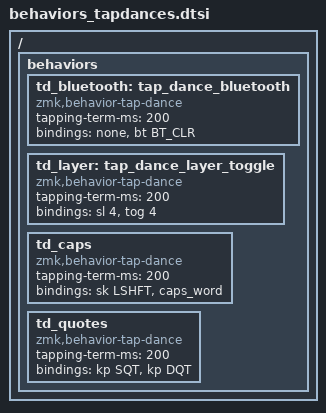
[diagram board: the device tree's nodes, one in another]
/ {

    behaviors {

        // double to clear a bluetooth profile to avoid mistrigger
        td_bluetooth: tap_dance_bluetooth {
            compatible = "zmk,behavior-tap-dance";
            #binding-cells = <0>;
            tapping-term-ms = <200>;
            bindings = <&none>, <&bt BT_CLR>;
        };

        // single tap - sticky layer 
        // double tap - tog
        td_layer: tap_dance_layer_toggle {
            compatible = "zmk,behavior-tap-dance";
            #binding-cells = <0>;
            tapping-term-ms = <200>;
            bindings = <&sl 4>, <&tog 4>;
        };  

        td_caps: td_caps {
            compatible = "zmk,behavior-tap-dance";
            #binding-cells = <0>;
            tapping-term-ms = <200>;
            bindings = <&sk LSHFT>, <&caps_word>;
        };

        td_quotes: td_quotes {
            compatible = "zmk,behavior-tap-dance";
            #binding-cells = <0>;
            tapping-term-ms = <200>;
            bindings = <&kp SQT>, <&kp DQT>;
        };
    };

};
